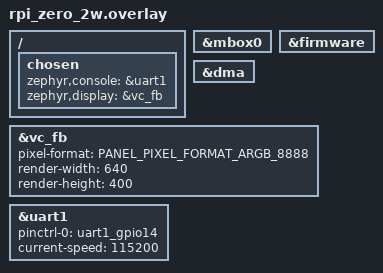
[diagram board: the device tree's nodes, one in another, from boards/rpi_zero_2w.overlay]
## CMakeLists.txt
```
# SPDX-License-Identifier: GPL-2.0-or-later
#
# PiZZa -- Faux86 (ArnoldUK/Faux86-remake) 8086 PC emulator on Zephyr.
#
# Faux86 has its own 5-method HostSystemInterface, so it does NOT use the
# SDL2 shim: the core links against a Zephyr host impl (src/faux86_host.cpp)
# that drives the app-local present seam + Zephyr timer directly.
#
# The upstream checkout stays pristine; the core src/ is gen-copied into the
# build dir with one Zephyr fixup (Types.h size_t clashes with picolibc).
#
# Faux86 is GPL-2.0-or-later; this binary is GPL-2.0 by linking it.

cmake_minimum_required(VERSION 3.20.0)

find_package(Zephyr REQUIRED HINTS $ENV{ZEPHYR_BASE})
project(pizza-faux86 LANGUAGES C CXX ASM)

# ── Faux86-remake tree (untouched) ──────────────────────────────────
if(NOT DEFINED FAUX86)
  set(FAUX86 "$ENV{HOME}/github/Faux86-remake")
endif()
if(NOT EXISTS "${FAUX86}/src/VM.cpp")
  message(FATAL_ERROR
    "Faux86-remake sources not found at ${FAUX86}. Clone "
    "https://github.com/ArnoldUK/Faux86-remake or pass -DFAUX86=<path>.")
endif()

# Gen-copy the core into the build dir with the one Zephyr fixup: Types.h
# typedefs size_t on the non-win32/non-arduino path, clashing with picolibc.
# Replace that typedef with <stddef.h>. Checkout stays pristine.
set(FAUX86_GEN ${CMAKE_BINARY_DIR}/faux86-gen)
execute_process(COMMAND ${CMAKE_COMMAND} -E copy_directory ${FAUX86}/src ${FAUX86_GEN})
execute_process(COMMAND sed -i.bak
  "s@typedef unsigned int size_t;@#include <stddef.h>@"
  ${FAUX86_GEN}/Types.h)

file(GLOB FAUX86_CORE_SRC ${FAUX86_GEN}/*.cpp)
list(REMOVE_ITEM FAUX86_CORE_SRC
  ${FAUX86_GEN}/netcard.cpp   # NE2000 -- needs libpcap, off by default
  ${FAUX86_GEN}/packet.cpp
)

# ── app-local glue ──────────────────────────────────────────────────
set(FAUX86_APP_SRC
  src/faux86_host.cpp
  src/faux86_main.cpp
  src/faux86_clock.c
  src/faux86_pack.S
)
if(CONFIG_FAUX86_PRESENT_SEMIHOST)
  list(APPEND FAUX86_APP_SRC src/faux86_present_semihost.c)
elseif(CONFIG_FAUX86_PRESENT_DISPLAY)
  list(APPEND FAUX86_APP_SRC src/faux86_present_display.c)
else()
  list(APPEND FAUX86_APP_SRC src/faux86_present_none.c)
endif()

target_sources(app PRIVATE ${FAUX86_CORE_SRC} ${FAUX86_APP_SRC})

target_include_directories(app PRIVATE
  ${CMAKE_CURRENT_SOURCE_DIR}/include   # <circle/*> shims (new/alloc/util/sched)
  ${FAUX86_GEN}                          # patched Types.h + core headers
  ${CMAKE_CURRENT_SOURCE_DIR}/src
)

# DEPTH=16 is the render path Faux86-remake actually implements (win32/Pi
# ship it; DEPTH=32's vga_framebuffer fill is unimplemented -> black frames).
# The host blit converts RGB565 -> XRGB for the present seam.
target_compile_definitions(app PRIVATE DEPTH=16)

# The core is upstream; silence its warnings (as the DOSBox-X port does).
set_source_files_properties(${FAUX86_CORE_SRC} PROPERTIES COMPILE_OPTIONS "-w")

# ── bake ROMs + boot floppy into rodata (.incbin) ───────────────────
# All four come straight from the (required) Faux86-remake checkout's
# data/ -- nothing copyrighted is duplicated into this repo. Override the
# boot floppy with -DFAUX86_FLOPPY=<path> (e.g. a Treasure Trap disk).
if(NOT DEFINED FAUX86_FLOPPY)
  set(FAUX86_FLOPPY ${FAUX86}/data/dosboot.img)
endif()
execute_process(COMMAND ${CMAKE_COMMAND} -E copy ${FAUX86}/data/pcxtbios.bin ${CMAKE_BINARY_DIR}/faux86_bios.bin)
execute_process(COMMAND ${CMAKE_COMMAND} -E copy ${FAUX86}/data/videorom.bin ${CMAKE_BINARY_DIR}/faux86_videorom.bin)
execute_process(COMMAND ${CMAKE_COMMAND} -E copy ${FAUX86}/data/asciivga.dat ${CMAKE_BINARY_DIR}/faux86_ascii.dat)
execute_process(COMMAND ${CMAKE_COMMAND} -E copy ${FAUX86_FLOPPY}            ${CMAKE_BINARY_DIR}/faux86_floppy.img)
set_source_files_properties(src/faux86_pack.S PROPERTIES
  COMPILE_OPTIONS "-I${CMAKE_BINARY_DIR};-Wa,-I${CMAKE_BINARY_DIR}"
)
```

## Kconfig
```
# SPDX-License-Identifier: GPL-2.0-or-later
#
# PiZZa Faux86 port -- app options.

menu "PiZZa Faux86 port"

choice FAUX86_PRESENT_BACKEND
	prompt "Frame present backend"
	default FAUX86_PRESENT_DISPLAY if DISPLAY
	default FAUX86_PRESENT_SEMIHOST if QEMU_TARGET
	default FAUX86_PRESENT_NONE

config FAUX86_PRESENT_DISPLAY
	bool "Zephyr display API (bcm2835_fb + HVS scaling on hardware)"
	depends on DISPLAY

config FAUX86_PRESENT_SEMIHOST
	bool "Semihosting PPM frame capture (qemu sim gates)"

config FAUX86_PRESENT_NONE
	bool "Discard frames"

endchoice

config FAUX86_CAPTURE_EVERY
	int "Capture every Nth frame (semihost backend)"
	depends on FAUX86_PRESENT_SEMIHOST
	default 30

config FAUX86_SCRIPTED_INPUT
	bool "Scripted keyboard input (sim verification)"
	default n

endmenu

source "Kconfig.zephyr"
```

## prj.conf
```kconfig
# SPDX-License-Identifier: GPL-2.0-or-later
#
# Common config for the PiZZa Faux86 port. Per-board overrides live in
# boards/<board>.conf. Faux86 is a pure 8086 INTERPRETER: no JIT, so no
# dynrec dual-map / RWX region / giant arena that the DOSBox-X port needed.

CONFIG_PRINTK=y
CONFIG_BOOT_BANNER=y

# picolibc errno needs TLS -- same stanza as wipeout/SDLPoP/Doom/DOSBox.
CONFIG_TOOLCHAIN_CROSS_COMPILE_SUPPORTS_THREAD_LOCAL_STORAGE=y
CONFIG_THREAD_LOCAL_STORAGE=y

# C++17 + real libstdc++ (aarch64 recipe: also pass
# -DTOOLCHAIN_HAS_GLIBCXX=ON on the west line). Faux86 uses virtual
# interfaces (RTTI/typeinfo) throughout.
CONFIG_CPP=y
CONFIG_STD_CPP17=y
CONFIG_GLIBCXX_LIBCPP=y
CONFIG_CPP_EXCEPTIONS=y
CONFIG_CPP_RTTI=y

# Guest RAM (1 MiB) + VGA memory (256 KiB) + the 800x800 XRGB render
# surface (~2.5 MiB) + RAM-staged boot floppy (~1.4 MiB) + STL. 16 MiB is
# comfortable on the 128 MiB (qemu) / 512 MiB (rpi_zero_2w) targets.
CONFIG_COMMON_LIBC_MALLOC_ARENA_SIZE=16777216

CONFIG_MAIN_STACK_SIZE=131072

CONFIG_FPU=y
CONFIG_STACK_SENTINEL=y
CONFIG_ASSERT=y
```

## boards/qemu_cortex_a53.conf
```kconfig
# SPDX-License-Identifier: GPL-2.0-or-later
# qemu sim gate: PPM frame capture over semihosting. Faux86's whole
# working set is a few MiB, so the board-default 128 MiB RAM is ample
# (no sram0 overlay / -m bump needed, unlike the DOSBox-X port).
CONFIG_SEMIHOST=y
# Faux86 boots the XT BIOS + DOS quickly under TCG; capture often.
CONFIG_FAUX86_CAPTURE_EVERY=10
```

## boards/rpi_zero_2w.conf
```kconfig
# SPDX-License-Identifier: GPL-2.0-or-later
#
# Raspberry Pi Zero 2 W (BCM2710, Cortex-A53, AArch64) -- Faux86.
# First HW light: XT BIOS POST + MS-DOS boot on the HDMI panel. Video
# goes to HDMI via the VC framebuffer, logs to the mini-UART console.
# Single core (Faux86 runs single-threaded), no USB, no audio yet.
# No dynrec/RWX config -- Faux86 is a pure interpreter.

CONFIG_BOOT_DELAY=200

# VC mailbox + firmware (framebuffer alloc chain + ARM clock bump).
CONFIG_RASPBERRYPI_FIRMWARE=y

# HDMI display via VC firmware FB, ARGB_8888, fixed 640x400 virtual mode;
# faux86_present_display.c scales each video mode into it and the HVS
# scales 640x400 to the monitor. Requires hdmi_drive=2 in config.txt.
CONFIG_DISPLAY=y
CONFIG_BCM2835_FB=y
CONFIG_DMA=y
CONFIG_DMA_BCM2835=y

# Logging on the mini-UART console.
CONFIG_LOG=y
CONFIG_LOG_BUFFER_SIZE=16384
CONFIG_LOG_BACKEND_UART=y
CONFIG_LOG_MODE_DEFERRED=y
```

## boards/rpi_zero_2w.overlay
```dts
/*
 * SPDX-License-Identifier: GPL-2.0-or-later
 *
 * PiZZa Faux86 overlay for rpi_zero_2w.
 *
 *   - &mbox0 + &firmware: VC mailbox + property tags (FB alloc + clock).
 *   - &vc_fb: HDMI framebuffer pinned at a fixed 640x400 virtual mode;
 *     faux86_present_display.c nearest-neighbor scales each Faux86 video
 *     mode into it and the VideoCore HVS scales 640x400 to the cable.
 *     The XT text mode is 640x400, so it lands 1:1. 640 * 4 = 2560
 *     bytes/row = 64-byte aligned, so the FB driver's contiguous-DMA
 *     fast path engages.
 *   - &dma: BCM2835 DMA (backbuffer -> fb blit).
 *   - mini-UART (uart1) console + LOG target, PiZZa convention.
 */

#include <zephyr/dt-bindings/display/panel.h>

&mbox0 {
	status = "okay";
};

&firmware {
	status = "okay";
};

&dma {
	status = "okay";
};

&vc_fb {
	pixel-format = <PANEL_PIXEL_FORMAT_ARGB_8888>;
	render-width = <640>;
	render-height = <400>;
	status = "okay";
};

/ {
	chosen {
		zephyr,console = &uart1;
		zephyr,display = &vc_fb;
	};
};

&uart1 {
	pinctrl-names = "default";
	pinctrl-0 = <&uart1_gpio14>;
	status = "okay";
	current-speed = <115200>;
};
```

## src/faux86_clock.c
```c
/* SPDX-License-Identifier: GPL-2.0-or-later */
/*
 * PiZZa Faux86 -- ARM clock bump (rpi_zero_2w).
 *
 * The VideoCore firmware idles the Cortex-A53 at arm_freq_min (~600 MHz)
 * unless something explicitly requests the turbo clock; Zephyr runs no
 * cpufreq governor. The 8086 interpreter is CPU-bound, so a boot-time
 * SET_CLOCK_RATE with skip_setting_turbo=0 pins the A53 at its rated
 * 1.0 GHz (measured ~1.6x on the Jet port). Opt-in per-app.
 */

#include <zephyr/kernel.h>
#include <zephyr/device.h>
#include <zephyr/sys/printk.h>

#if defined(CONFIG_RASPBERRYPI_FIRMWARE)

#include <rpi_fw.h>

#define VC_CLOCK_ID_ARM 3U
#define ARM_TARGET_HZ   1000000000U

void faux86_bump_arm_clock(void)
{
	const struct device *fw = DEVICE_DT_GET_ONE(raspberrypi_bcm283x_firmware);

	if (!device_is_ready(fw)) {
		printk("[faux86] VC firmware not ready -- ARM stays at idle clock\n");
		return;
	}

	uint32_t cur[2] = {VC_CLOCK_ID_ARM, 0U};

	rpi_fw_transfer(fw, RPI_FW_TAG_GET_CLOCK_RATE, cur, sizeof(cur));

	uint32_t req[3] = {VC_CLOCK_ID_ARM, ARM_TARGET_HZ, 0U /* skip_setting_turbo */};
	int err = rpi_fw_transfer(fw, RPI_FW_TAG_SET_CLOCK_RATE, req, sizeof(req));

	uint32_t post[2] = {VC_CLOCK_ID_ARM, 0U};

	rpi_fw_transfer(fw, RPI_FW_TAG_GET_CLOCK_RATE, post, sizeof(post));

	printk("[faux86] ARM clock: %u -> %u Hz (SET err=%d)\n",
	       (unsigned)cur[1], (unsigned)post[1], err);
}

#else /* no VC firmware (e.g. qemu) */

void faux86_bump_arm_clock(void) {}

#endif
```

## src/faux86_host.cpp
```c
/* SPDX-License-Identifier: GPL-2.0-or-later */
/*
 * PiZZa Faux86 -- Zephyr HostSystemInterface impl. Present goes through the
 * app-local s2s_present_* seam (semihost PPM on qemu, bcm2835_fb on HW);
 * timing is Zephyr cycles; audio is a silent stub for now (MAI is a later
 * phase); disks are handed to Config directly by faux86_main, so openFile
 * is unused.
 */
#include <zephyr/kernel.h>
#include <zephyr/sys/printk.h>

#include <cstdarg>
#include <cstdio>

#include "Config.h"
#include "Types.h"
#include "HostSystemInterface.h"
#include "Renderer.h"
#include "VM.h"
#include "DriveManager.h"

#include "faux86_host.h"
#include "faux86_present.h"

using namespace Faux86;

/* Faux86 requires the host to provide log(). */
namespace Faux86 {
void log(LogChannel channel, const char *message, ...)
{
	char buf[256];
	va_list args;

	va_start(args, message);
	vsnprintf(buf, sizeof(buf), message, args);
	va_end(args);

	if (channel == LogRaw) {
		printk("%s", buf);
	} else {
		printk("%s\n", buf);
	}
}
} /* namespace Faux86 */

/*
 * The base HostSystemInterface declares non-pure init()/resize() with no
 * bodies (derived classes override them). Define them out-of-line so the
 * vtable + typeinfo are emitted (Itanium ABI key-function rule; MSVC/Circle
 * tolerate the omission, aarch64 does not).
 */
void Faux86::HostSystemInterface::init(VM *inVM) { (void)inVM; }
void Faux86::HostSystemInterface::resize(uint32_t w, uint32_t h) { (void)w; (void)h; }

/* ---------------------------------------------------------------- FrameBuffer */
void Faux86FrameBufferInterface::init(uint32_t w, uint32_t h)
{
	resize(w, h);
}

void Faux86FrameBufferInterface::resize(uint32_t w, uint32_t h)
{
	renderSurface.width = w;
	renderSurface.height = h;
	renderSurface.pitch = w;
	/*
	 * pixels intentionally left null: the active render path converts VGA
	 * memory to XRGB and hands that buffer straight to blit(). getSurface()
	 * is only stashed by Renderer::init (same as the SDL frontend).
	 */
}

RenderSurface *Faux86FrameBufferInterface::getSurface()
{
	return &renderSurface;
}

void Faux86FrameBufferInterface::setPalette(Palette *palette)
{
	(void)palette;
}

#if defined(ARDUINO) || (VIDEO_FRAMEBUFFER_DEPTH == 16)
void Faux86FrameBufferInterface::blit(uint16_t *pixels, int w, int h, int stride)
{
	/* Faux86 emits RGB565 (uint16_t); the present seam wants 32bpp XRGB. */
	size_t need = (size_t)w * (size_t)h * sizeof(uint32_t);

	if (need > xrgb_cap) {
		free(xrgb);
		xrgb = (uint32_t *)malloc(need);
		xrgb_cap = (xrgb != nullptr) ? need : 0;
	}
	if (xrgb == nullptr) {
		return;
	}

	for (int y = 0; y < h; y++) {
		const uint16_t *src = (const uint16_t *)((const uint8_t *)pixels + (size_t)stride * y);
		uint32_t *dst = xrgb + (size_t)w * y;

		for (int x = 0; x < w; x++) {
			uint16_t p = src[x];
			uint32_t r = (p >> 11) & 0x1F;
			uint32_t g = (p >> 5) & 0x3F;
			uint32_t b = p & 0x1F;

			dst[x] = (((r << 3) | (r >> 2)) << 16) |
				 (((g << 2) | (g >> 4)) << 8) |
				 ((b << 3) | (b >> 2));
		}
	}

	if (w != cur_w || h != cur_h) {
		s2s_present_init(w, h);
		cur_w = w;
		cur_h = h;
	}
	s2s_present_frame(xrgb, w * (int)sizeof(uint32_t));
}
#else
void Faux86FrameBufferInterface::blit(uint32_t *pixels, int w, int h, int stride)
{
	if (w != cur_w || h != cur_h) {
		s2s_present_init(w, h);
		cur_w = w;
		cur_h = h;
	}
	s2s_present_frame(pixels, stride);
}
#endif

/* --------------------------------------------------------------------- Timer */
uint64_t Faux86TimerInterface::getHostFreq()
{
	return (uint64_t)sys_clock_hw_cycles_per_sec();
}

uint64_t Faux86TimerInterface::getTicks()
{
	return k_cycle_get_64();
}

/* --------------------------------------------------------------------- Audio */
void Faux86AudioInterface::init(VM &vm)
{
	(void)vm;
	printk("[faux86] audio: silent stub (MAI backend is a later phase)\n");
}

void Faux86AudioInterface::shutdown() {}

/* ---------------------------------------------------------------- HostSystem */
Faux86HostSystemInterface::Faux86HostSystemInterface() {}

void Faux86HostSystemInterface::init(VM *inVM)
{
	vm = inVM;
}

void Faux86HostSystemInterface::resize(uint32_t w, uint32_t h)
{
	scrWidth = w;
	scrHeight = h;
}

DiskInterface *Faux86HostSystemInterface::openFile(const char *filename)
{
	(void)filename;
	return nullptr; /* disks are set directly on Config by faux86_main */
}

void Faux86HostSystemInterface::tick()
{
	/* input pump lands here in a later phase */
}
```

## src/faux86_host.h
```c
/* SPDX-License-Identifier: GPL-2.0-or-later */
/*
 * PiZZa Faux86 -- Zephyr implementation of Faux86's HostSystemInterface.
 * Mirrors the structure of win32/SDLInterface.cpp but drives the PiZZa
 * backends directly (present seam / Zephyr timer), no SDL.
 */
#pragma once

#include "Config.h"
#include "Types.h"
#include "HostSystemInterface.h"
#include "Renderer.h"

namespace Faux86 {

class VM;
class DiskInterface;

class Faux86FrameBufferInterface : public FrameBufferInterface {
public:
	void init(uint32_t desiredWidth, uint32_t desiredHeight) override;
	void resize(uint32_t desiredWidth, uint32_t desiredHeight) override;
	RenderSurface *getSurface() override;
	void setPalette(Palette *palette) override;
#if defined(ARDUINO) || (VIDEO_FRAMEBUFFER_DEPTH == 16)
	void blit(uint16_t *pixels, int w, int h, int stride) override;
#else
	void blit(uint32_t *pixels, int w, int h, int stride) override;
#endif

private:
	RenderSurface renderSurface{};
	int cur_w = -1;
	int cur_h = -1;
	uint32_t *xrgb = nullptr;   /* RGB565 -> XRGB scratch for the present seam */
	size_t xrgb_cap = 0;
};

class Faux86TimerInterface : public TimerInterface {
public:
	uint64_t getHostFreq() override;
	uint64_t getTicks() override;
};

class Faux86AudioInterface : public AudioInterface {
public:
	void init(VM &vm) override;
	void shutdown() override;
};

class Faux86HostSystemInterface : public HostSystemInterface {
public:
	Faux86HostSystemInterface();
	void init(VM *inVM) override;
	void resize(uint32_t desiredWidth, uint32_t desiredHeight) override;
	FrameBufferInterface &getFrameBuffer() override { return frameBufferInterface; }
	TimerInterface &getTimer() override { return timerInterface; }
	AudioInterface &getAudio() override { return audioInterface; }
	DiskInterface *openFile(const char *filename) override;
	void tick();

private:
	Faux86FrameBufferInterface frameBufferInterface;
	Faux86TimerInterface timerInterface;
	Faux86AudioInterface audioInterface;
};

} /* namespace Faux86 */
```

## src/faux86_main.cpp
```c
/* SPDX-License-Identifier: GPL-2.0-or-later */
/*
 * PiZZa Faux86 -- Zephyr entry point. Mirrors win32/main.cpp's
 * Config -> VM -> simulate() loop, with the ROMs + boot floppy handed in as
 * EmbeddedDisks over .incbin rodata (faux86_pack.S) instead of the command
 * line / files.
 */
#include <zephyr/kernel.h>
#include <zephyr/sys/printk.h>

#include "Config.h"
#include "VM.h"
#include "DriveManager.h"
#include "faux86_host.h"

using namespace Faux86;

extern "C" {
extern const uint8_t faux86_bios_start[];
extern const uint8_t faux86_bios_end[];
extern const uint8_t faux86_videorom_start[];
extern const uint8_t faux86_videorom_end[];
extern const uint8_t faux86_ascii_start[];
extern const uint8_t faux86_ascii_end[];
extern const uint8_t faux86_floppy_start[];
extern const uint8_t faux86_floppy_end[];
}

extern "C" void faux86_bump_arm_clock(void);

static Faux86HostSystemInterface hostInterface;
static Faux86::VM *vm86;

int main(void)
{
	printk("[faux86] PiZZa Faux86 port -- board %s\n", CONFIG_BOARD);

	faux86_bump_arm_clock();

	Config cfg(&hostInterface);
	cfg.singleThreaded = true;
	cfg.enableAudio = false;
	cfg.enableConsole = false;
	cfg.enableMenu = false;
	cfg.cpuType = CPU_TYPE_V20;
	cfg.cpuSpeed = 0; /* uncapped: reach the POST banner faster under slow TCG */

	cfg.biosFile = new EmbeddedDisk((uint8_t *)faux86_bios_start,
		(uint64_t)(faux86_bios_end - faux86_bios_start));
	cfg.videoRomFile = new EmbeddedDisk((uint8_t *)faux86_videorom_start,
		(uint64_t)(faux86_videorom_end - faux86_videorom_start));
	cfg.asciiFile = new EmbeddedDisk((uint8_t *)faux86_ascii_start,
		(uint64_t)(faux86_ascii_end - faux86_ascii_start));
	cfg.diskDriveA = new EmbeddedDisk((uint8_t *)faux86_floppy_start,
		(uint64_t)(faux86_floppy_end - faux86_floppy_start));
	cfg.bootDrive = 0; /* fd0 = A: */

	printk("[faux86] roms: bios=%u videorom=%u ascii=%u floppy=%u bytes\n",
		(unsigned)(faux86_bios_end - faux86_bios_start),
		(unsigned)(faux86_videorom_end - faux86_videorom_start),
		(unsigned)(faux86_ascii_end - faux86_ascii_start),
		(unsigned)(faux86_floppy_end - faux86_floppy_start));

	vm86 = new VM(cfg);

	if (vm86->init()) {
		hostInterface.init(vm86);
		printk("[faux86] entering emulation loop\n");

		while (vm86->simulate()) {
			hostInterface.tick();
		}
	} else {
		printk("[faux86] VM init failed\n");
	}

	printk("[faux86] emulation ended\n");
	return 0;
}
```

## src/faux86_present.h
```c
/* SPDX-License-Identifier: GPL-2.0-or-later */
/*
 * Frame present seam for the PiZZa Faux86 port. The chosen backend
 * (semihost PPM / bcm2835_fb display / none) implements these; the Faux86
 * host FrameBufferInterface::blit() calls them. Pixels are 32bpp XRGB
 * (0x00RRGGBB), which is what Faux86 emits when built with DEPTH=32.
 */
#pragma once

#ifdef __cplusplus
extern "C" {
#endif

int s2s_present_init(int width, int height);
void s2s_present_frame(const void *xrgb_pixels, int pitch);

#ifdef __cplusplus
}
#endif
```

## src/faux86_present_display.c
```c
/* SPDX-License-Identifier: GPL-2.0-or-later */
/*
 * PiZZa Faux86 -- display present backend (CONFIG_FAUX86_PRESENT_DISPLAY).
 *
 * Faux86 changes video mode at runtime (XT text 640x400, CGA 320x200,
 * EGA 640x350, ...), but the Zephyr display API has a fixed resolution
 * set at probe. So the VC framebuffer is pinned at a fixed 640x400
 * virtual mode (render-width/height in the overlay) and each incoming
 * frame is nearest-neighbor scaled into it; the VideoCore HVS then
 * scales 640x400 to the monitor's native mode -- the same proven trick
 * as the Jet / wipeout / SDLPoP / Doom / DOSBox-X ports.
 *
 * 640x400 is chosen so the XT text mode (80x25, 8x16 font) lands 1:1.
 * The host blit hands over 0x00RRGGBB; scanout wants 0xFFRRGGBB, so
 * alpha is forced opaque.
 */

#include <zephyr/kernel.h>
#include <zephyr/device.h>
#include <zephyr/drivers/display.h>
#include <zephyr/logging/log.h>

#include "faux86_present.h"

LOG_MODULE_REGISTER(faux86_present, LOG_LEVEL_INF);

#define FB_W 640
#define FB_H 400

static const struct device *display_dev;
static uint32_t backbuf[FB_W * FB_H];
static bool ready;

static int src_w, src_h;
static uint16_t xmap[FB_W]; /* src column for each dst column */

int s2s_present_init(int width, int height)
{
	src_w = width;
	src_h = height;

	for (int x = 0; x < FB_W; x++) {
		int sx = (int)((int64_t)x * src_w / FB_W);

		xmap[x] = (uint16_t)(sx < src_w ? sx : src_w - 1);
	}

	if (ready) {
		LOG_INF("present: mode -> %dx%d (VFB %dx%d)", src_w, src_h, FB_W, FB_H);
		return 0;
	}

	display_dev = DEVICE_DT_GET(DT_CHOSEN(zephyr_display));
	if (!device_is_ready(display_dev)) {
		LOG_ERR("present: display device not ready -- HDMI not connected?");
		return -ENODEV;
	}

	struct display_capabilities caps;

	display_get_capabilities(display_dev, &caps);
	LOG_INF("present: VFB %ux%u (HVS virt) fmt=0x%x; first src %dx%d",
		caps.x_resolution, caps.y_resolution,
		(unsigned int)caps.current_pixel_format, src_w, src_h);

	if (caps.x_resolution != FB_W || caps.y_resolution != FB_H) {
		LOG_WRN("present: display reports %ux%u, expected %ux%u "
			"(check render-width/render-height in overlay)",
			caps.x_resolution, caps.y_resolution, FB_W, FB_H);
	}

	ready = true;
	return 0;
}

void s2s_present_frame(const void *xrgb_pixels, int pitch)
{
	if (!ready || src_w <= 0 || src_h <= 0) {
		return;
	}

	const uint8_t *src_base = xrgb_pixels;
	uint32_t *dst = backbuf;

	for (int y = 0; y < FB_H; y++) {
		int sy = (int)((int64_t)y * src_h / FB_H);

		if (sy >= src_h) {
			sy = src_h - 1;
		}
		const uint32_t *srow = (const uint32_t *)(src_base + (size_t)sy * pitch);

		if (src_w == FB_W) {
			/* text-mode fast path: 1:1 columns, just force alpha */
			for (int x = 0; x < FB_W; x++) {
				dst[x] = 0xFF000000u | (srow[x] & 0x00FFFFFFu);
			}
		} else {
			for (int x = 0; x < FB_W; x++) {
				dst[x] = 0xFF000000u | (srow[xmap[x]] & 0x00FFFFFFu);
			}
		}
		dst += FB_W;
	}

	struct display_buffer_descriptor desc = {
		.buf_size = sizeof(backbuf),
		.width = FB_W,
		.height = FB_H,
		.pitch = FB_W,
		.frame_incomplete = false,
	};

	int rc = display_write(display_dev, 0, 0, &desc, backbuf);

	if (rc != 0) {
		LOG_ERR("present: display_write rc=%d", rc);
	}
}
```

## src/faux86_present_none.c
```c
/* SPDX-License-Identifier: GPL-2.0-or-later */
/* PiZZa Faux86 -- discard frames (CONFIG_FAUX86_PRESENT_NONE). */

#include "faux86_present.h"

int s2s_present_init(int width, int height)
{
	(void)width;
	(void)height;
	return 0;
}

void s2s_present_frame(const void *xrgb_pixels, int pitch)
{
	(void)xrgb_pixels;
	(void)pitch;
}
```

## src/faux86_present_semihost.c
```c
/*
 * SPDX-License-Identifier: GPL-2.0-or-later
 *
 * PiZZa Faux86 -- semihosting capture present backend
 * (CONFIG_FAUX86_PRESENT_SEMIHOST, qemu sim gate). DOSBox-port pattern:
 * frames land on the host as binary PPM (P6); pixels are 32bpp XRGB.
 *
 * Frame 1 is always written; every CONFIG_FAUX86_CAPTURE_EVERY'th frame
 * after that. A mode change (new width/height) resets the counter so the
 * first frame of each new mode is captured too.
 */

#include <zephyr/kernel.h>
#include <zephyr/arch/common/semihost.h>
#include <zephyr/sys/printk.h>
#include <stdio.h>

#include "faux86_present.h"

#define MAX_W 1280

static int fb_w;
static int fb_h;
static uint32_t frames;
static uint32_t captures;

int s2s_present_init(int width, int height)
{
	if (width > MAX_W) {
		printk("[faux86] present: width %d > MAX_W %d\n", width, MAX_W);
		return -1;
	}
	fb_w = width;
	fb_h = height;
	frames = 0;
	printk("[faux86] present: semihost capture backend (%dx%d)\n", width, height);
	return 0;
}

void s2s_present_frame(const void *xrgb_pixels, int pitch)
{
	frames++;

	/*
	 * Only capture frames with drawn content -- skip the all-black cleared
	 * screen the BIOS shows during early POST (under slow TCG that is most
	 * of them). If nothing is ever non-black, zero PPMs get written, which
	 * cleanly distinguishes a real render bug from a slow boot.
	 */
	const uint8_t *base = xrgb_pixels;
	bool has_content = false;

	for (int y = 0; y < fb_h && !has_content; y++) {
		const uint32_t *px = (const uint32_t *)(base + (size_t)pitch * y);

		for (int x = 0; x < fb_w; x++) {
			if (px[x] & 0x00FFFFFFu) {
				has_content = true;
				break;
			}
		}
	}
	if (!has_content) {
		if ((frames % 500) == 0) {
			printk("[faux86] present: frame %u still blank\n", frames);
		}
		return;
	}

	/* throttle content captures so a busy screen doesn't flood the host */
	if (captures > 0 && CONFIG_FAUX86_CAPTURE_EVERY > 0 &&
	    (frames % CONFIG_FAUX86_CAPTURE_EVERY) != 0) {
		return;
	}

	char name[48];
	char header[32];

	snprintf(name, sizeof(name), "faux86_frame_%06u.ppm", ++captures);

	long fd = semihost_open(name, SEMIHOST_OPEN_WB);

	if (fd < 0) {
		printk("[faux86] present: semihost_open(%s) = %ld\n", name, fd);
		return;
	}

	int hlen = snprintf(header, sizeof(header), "P6\n%d %d\n255\n", fb_w, fb_h);

	semihost_write(fd, header, hlen);

	static uint8_t rowbuf[MAX_W * 3];
	const uint8_t *row = xrgb_pixels;

	for (int y = 0; y < fb_h; y++) {
		const uint32_t *px = (const uint32_t *)row;
		uint8_t *o = rowbuf;

		for (int x = 0; x < fb_w; x++) {
			uint32_t p = px[x];

			*o++ = (uint8_t)(p >> 16);
			*o++ = (uint8_t)(p >> 8);
			*o++ = (uint8_t)(p);
		}
		semihost_write(fd, rowbuf, (long)fb_w * 3);
		row += pitch;
	}
	semihost_close(fd);
	printk("[faux86] present: wrote %s (frame %u, %dx%d)\n", name, frames, fb_w, fb_h);
}
```
